# HK32L0xx register map
Vendor: HKMicroChip Ltd.; Series: HK32L0xx; File version: 1.3
CPU: CM0 r0p0, little endian, no MPU, no FPU, 3 interrupt priority bits
Registers are 32-bit, read-write, reset 0x0 unless marked. A register's access mark holds for its fields unless they carry their own. Offsets are from the block's base; [hi:lo] are bit positions; lines under a group give offsets from that group; {n}, {i} and the like mark numbered series; 'fields as' and 'values as' point back to an identical list.

## EMACC
Base 0x40028000
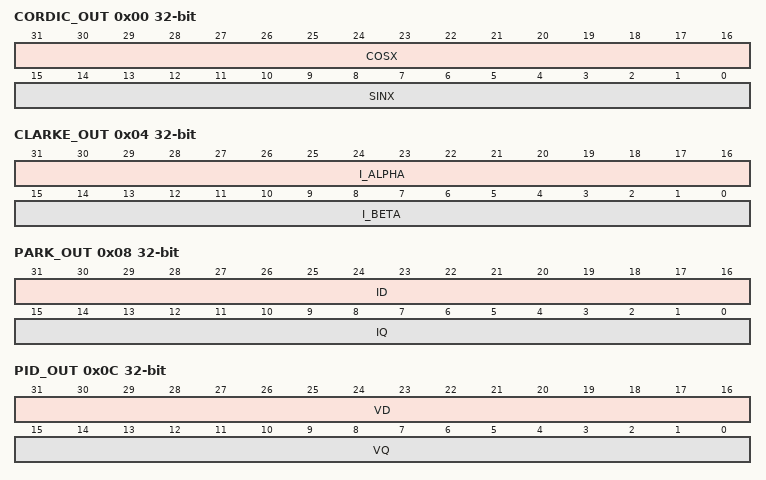
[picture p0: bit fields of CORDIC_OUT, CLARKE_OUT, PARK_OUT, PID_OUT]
0x00 CORDIC_OUT ro
  [31:16] COSX — Cossine X value
  [15:0] SINX — Sinusoidal X value
0x04 CLARKE_OUT ro
  [31:16] I_ALPHA — Output result, Alpha axis of clarke transformation
  [15:0] I_BETA — Output result, Beta axis of clarke transformation
0x08 PARK_OUT ro
  [31:16] ID — Output result, D axis of park transform
  [15:0] IQ — Output result, Q axis of park transform
0x0C PID_OUT ro
  [31:16] VD — Output result, D axis of pid module
  [15:0] VQ — Output result, Q axis of pid module
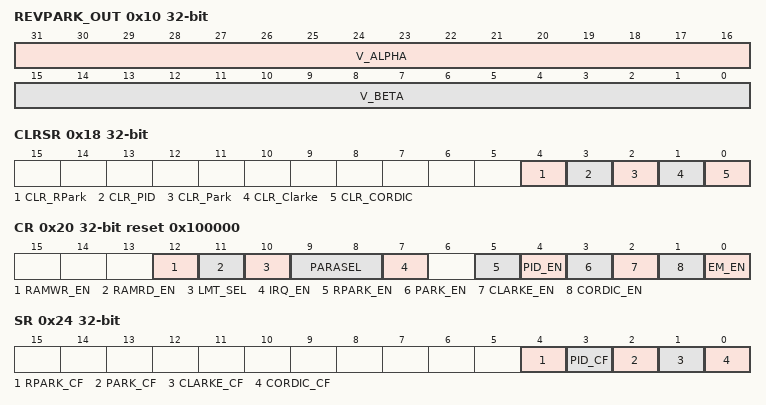
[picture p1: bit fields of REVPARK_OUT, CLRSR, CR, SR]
0x10 REVPARK_OUT ro
  [31:16] V_ALPHA — Output VAlpha axis of Reverse park Transform Module
  [15:0] V_BETA — Output VBeta axis of Reverse park Transform Module
0x18 CLRSR wo
  [4] CLR_RPark — Reverse-PARK data ready flag clear
  [3] CLR_PID — PID data ready flag clear
  [2] CLR_Park — PARK data ready flag clear
  [1] CLR_Clarke — CLARKE data ready flag clear
  [0] CLR_CORDIC — CORDIC data ready flag clear
0x20 CR reset 0x100000
  [12] RAMWR_EN — SRAM write access from AHB interface
  [11] RAMRD_EN — SRAM Read access from AHB interface
  [10] LMT_SEL — Select the limit value register
  [9:8] PARASEL — Select one group of PID parameter from 2 groups
  [7] IRQ_EN — Interrupt enable
  [5] RPARK_EN — Reverse park transformation enable
  [4] PID_EN — PID module enable
  [3] PARK_EN — Park transformation enable
  [2] CLARKE_EN — Clarke transformation enable
  [1] CORDIC_EN — Cordic module enable
  [0] EM_EN — Electric Motor acceleration module enable
0x24 SR ro
  [4] RPARK_CF — Reverse-PARK transformation complete flag
  [3] PID_CF — PID transformation complete flag
  [2] PARK_CF — PARK transformation complete flag
  [1] CLARKE_CF — CLARKE transformation complete flag
  [0] CORDIC_CF — CORDIC transformation complete flag
0x28 ANG_LDR
  [15:0] ANGLE_IN — Angle input
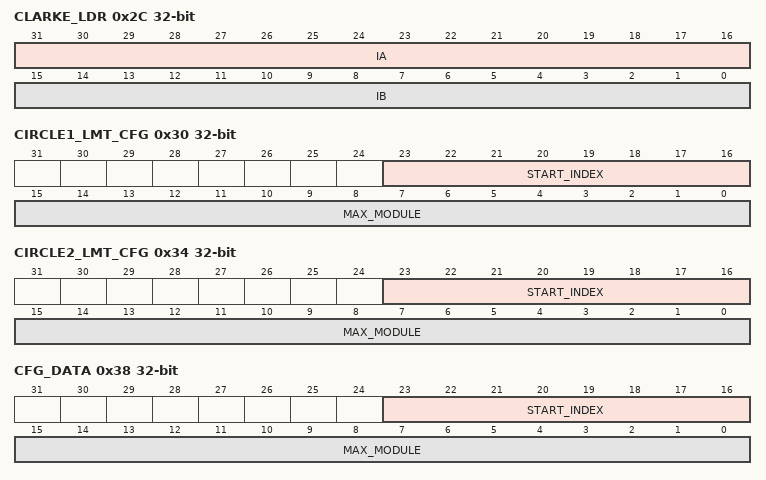
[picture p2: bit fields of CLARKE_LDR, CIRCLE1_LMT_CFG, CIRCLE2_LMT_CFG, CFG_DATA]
0x2C CLARKE_LDR
  [31:16] IA — IA phase A current value sampled by ADC
  [15:0] IB — IB phase B current value sampled by ADC
0x30 CIRCLE1_LMT_CFG wo
  [23:16] START_INDEX — Initiate index value of limit control array of group x
  [15:0] MAX_MODULE — Limit Ring Control Maximum of group x
0x34 CIRCLE2_LMT_CFG wo
  fields as CIRCLE1_LMT_CFG
0x38 CFG_DATA ro
  [23:16] START_INDEX — Initiate index value of limit control array
  [15:0] MAX_MODULE — Limit Ring Control Maximum
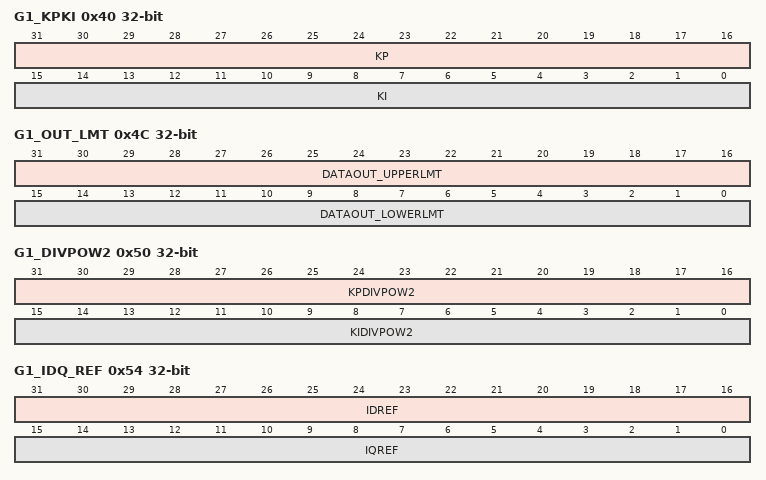
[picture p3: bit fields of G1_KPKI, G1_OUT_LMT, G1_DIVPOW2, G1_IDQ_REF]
0x40 G1_KPKI wo
  [31:16] KP — PID Group x gain parameter for proportion computation
  [15:0] KI — PID Group x gain parameter for integration computation
0x44 G1_INT_UPPRLMT wo
  [31:0] INT_UPPERLMT — PID Group x integration part interation upper limit
0x48 G1_INT_LOWERLMT wo
  [31:0] INT_LOWERLMT — PID Group x integration part interation lower limit
0x4C G1_OUT_LMT wo
  [31:16] DATAOUT_UPPERLMT — PID Group x PI module output data upper limit value
  [15:0] DATAOUT_LOWERLMT — PID Group x PI module output data lower limit value
0x50 G1_DIVPOW2 wo
  [31:16] KPDIVPOW2 — PID Group x PI module production part divisor parameter, the number of bits shifted by right
  [15:0] KIDIVPOW2 — PID Group x PI module integration part divisor parameter, the number of bits shifted by right
0x54 G1_IDQ_REF wo
  [31:16] IDREF — PID Group x module D channel reference input
  [15:0] IQREF — PID Group x module Q channel reference input
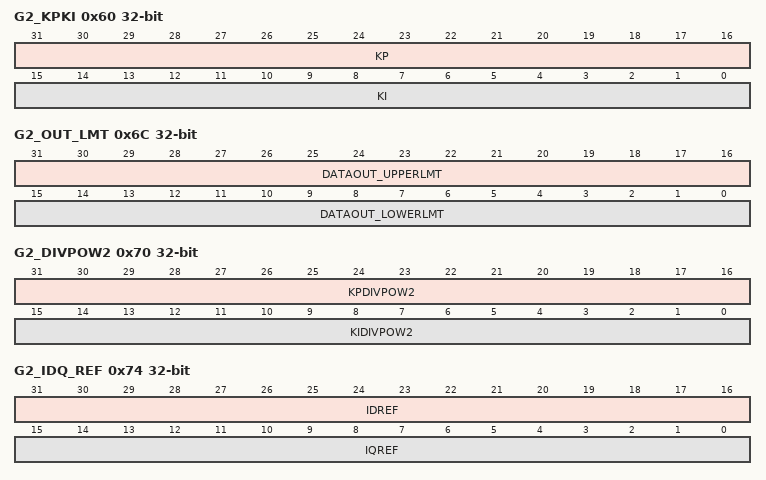
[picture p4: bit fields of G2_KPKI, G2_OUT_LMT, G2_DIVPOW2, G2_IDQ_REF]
0x60 G2_KPKI wo
  fields as G1_KPKI
0x64 G2_INT_UPPRLMT wo
  fields as G1_INT_UPPRLMT
0x68 G2_INT_LOWERLMT wo
  fields as G1_INT_LOWERLMT
0x6C G2_OUT_LMT wo
  fields as G1_OUT_LMT
0x70 G2_DIVPOW2 wo
  fields as G1_DIVPOW2
0x74 G2_IDQ_REF wo
  fields as G1_IDQ_REF
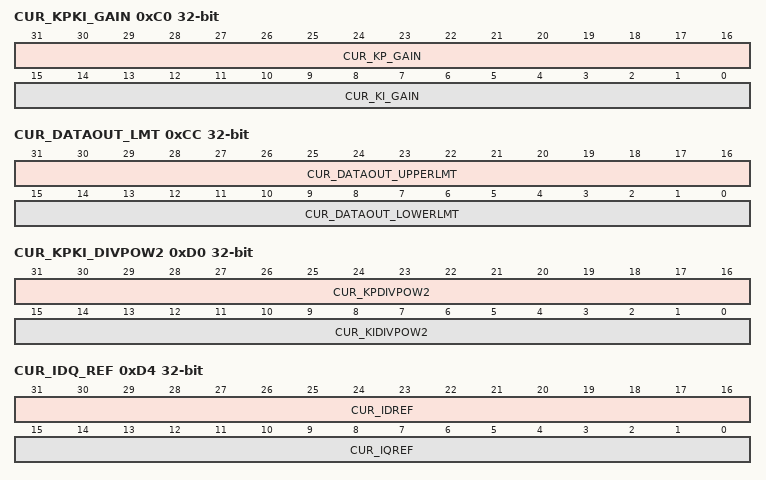
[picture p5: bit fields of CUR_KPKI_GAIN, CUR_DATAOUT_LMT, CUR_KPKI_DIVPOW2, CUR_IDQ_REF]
0xC0 CUR_KPKI_GAIN ro
  [31:16] CUR_KP_GAIN — Current KP gain configuration
  [15:0] CUR_KI_GAIN — Current KI gain configuration
0xC4 CUR_INT_UPPERLMT ro
  [31:0] CUR_INT_UPPERLMT — Current integral upper limit value
0xC8 CUR_INT_LOWERLMT ro
  [31:0] CUR_INT_LOWERLMT — Current integral lower limit value
0xCC CUR_DATAOUT_LMT ro
  [31:16] CUR_DATAOUT_UPPERLMT — Current dataout upper limit value
  [15:0] CUR_DATAOUT_LOWERLMT — Current dataout lower limit value
0xD0 CUR_KPKI_DIVPOW2 ro
  [31:16] CUR_KPDIVPOW2 — Current KP: the number of bits shifted by right
  [15:0] CUR_KIDIVPOW2 — Current KI: the number of bits shifted by right
0xD4 CUR_IDQ_REF ro
  [31:16] CUR_IDREF — D channel reference input
  [15:0] CUR_IQREF — Q channel reference input
{0x100+4i} PID_RAM_SPACE{i} (i=0..63)
  [31:0] RAMDATA — MMITABLE data load to EMACC
